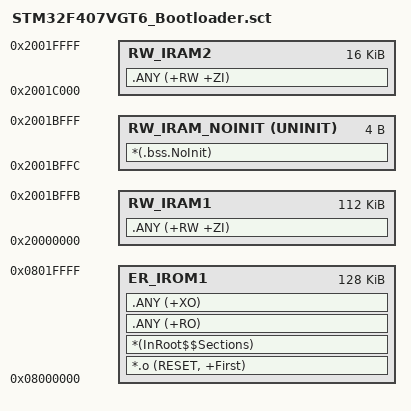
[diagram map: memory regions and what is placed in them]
; *************************************************************
; *** Scatter-Loading Description File generated by uVision ***
; *************************************************************

LR_IROM1 0x08000000 0x00020000  {    ; load region: Bootloader 128KB (Sector 0-4)
  ER_IROM1 0x08000000 0x00020000  {  ; load address = execution address
   *.o (RESET, +First)
   *(InRoot$$Sections)
   .ANY (+RO)
   .ANY (+XO)
  }
  RW_IRAM1 0x20000000 0x0001BFFC  {  ; RW data
   .ANY (+RW +ZI)
  }
  RW_IRAM2 0x2001C000 0x00004000  {
   .ANY (+RW +ZI)
  }
  RW_IRAM_NOINIT 0x2001BFFC UNINIT 0x00000004  {  ; NoInit RAM for bootloader/app communication
   *(.bss.NoInit)
  }
}
